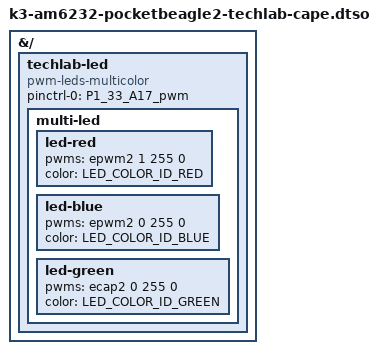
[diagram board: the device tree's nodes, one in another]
/dts-v1/;
/plugin/;

#include <dt-bindings/leds/common.h>

&{/} {
	techlab-led {
		compatible = "pwm-leds-multicolor";
		pinctrl-names = "default";
		pinctrl-0 = <&P1_33_A17_pwm>;

        	multi-led {
			led-red {
				pwms = <&epwm2 1 255 0>;
				color = <LED_COLOR_ID_RED>;
			};

        		led-blue {
				pwms = <&epwm2 0 255 0>;
				color = <LED_COLOR_ID_BLUE>;
			};

        		led-green {
				pwms = <&ecap2 0 255 0>;
				color = <LED_COLOR_ID_GREEN>;
			};
		};
	};
};
